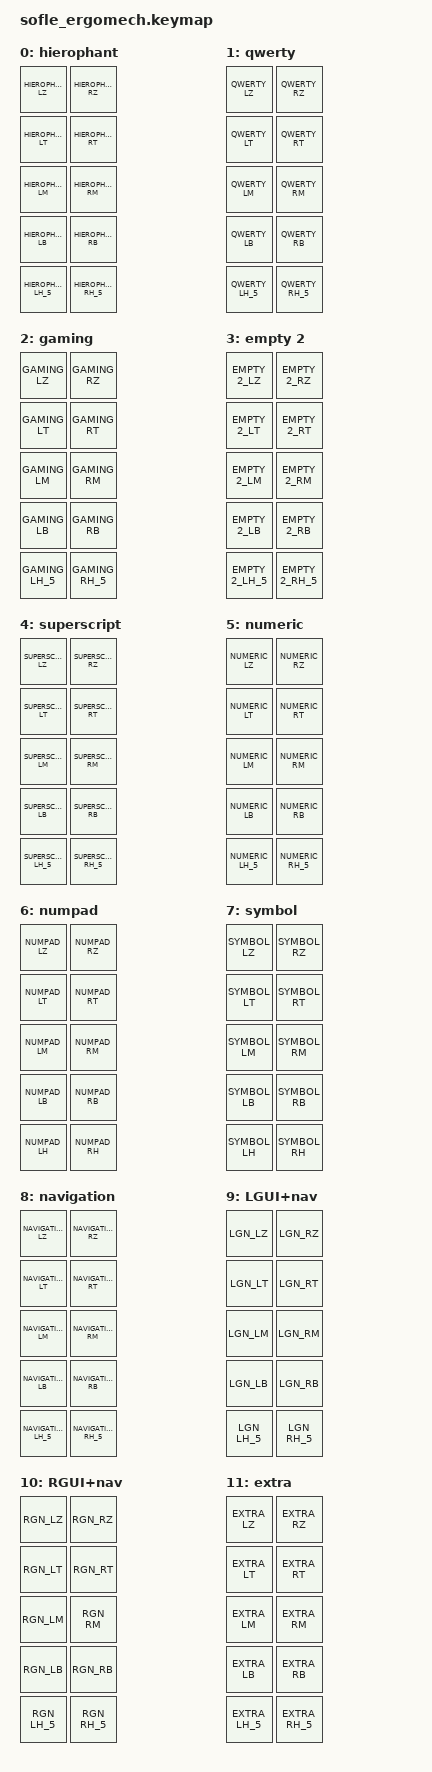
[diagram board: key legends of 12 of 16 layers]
#define CONFIG_WIRELESS

#include "zmk-helpers/key-labels/sofle.h"
#include "jjb.keymap"

/ {
    keymap {
        compatible = "zmk,keymap";

	hierophant_layer {
				display-name = "hierophant";
				bindings = <
HIEROPHANT_LZ HIEROPHANT_RZ
HIEROPHANT_LT HIEROPHANT_RT
HIEROPHANT_LM HIEROPHANT_RM
HIEROPHANT_LB HIEROPHANT_RB
HIEROPHANT_LH_5 HIEROPHANT_RH_5
				>;
            sensor-bindings = <&inc_dec_kp C_VOL_UP C_VOL_DN &inc_dec_kp PG_UP PG_DN>;
	};


        qwerty_layer {
            display-name = "qwerty";
            bindings = <
QWERTY_LZ QWERTY_RZ
QWERTY_LT QWERTY_RT
QWERTY_LM QWERTY_RM
QWERTY_LB QWERTY_RB
QWERTY_LH_5 QWERTY_RH_5
				>;				
            sensor-bindings = <&inc_dec_kp C_VOL_UP C_VOL_DN &inc_dec_kp PG_UP PG_DN>;
        };


        gaming_layer {
            display-name = "gaming";
            bindings = <
GAMING_LZ GAMING_RZ
GAMING_LT GAMING_RT
GAMING_LM GAMING_RM
GAMING_LB GAMING_RB
GAMING_LH_5 GAMING_RH_5
             >;
            sensor-bindings = <&inc_dec_kp C_VOL_UP C_VOL_DN &inc_dec_kp PG_UP PG_DN>;
        };

	empty_2_layer {
		display-name = "empty 2";
		bindings = <
EMPTY_2_LZ EMPTY_2_RZ
EMPTY_2_LT EMPTY_2_RT
EMPTY_2_LM EMPTY_2_RM
EMPTY_2_LB EMPTY_2_RB
EMPTY_2_LH_5 EMPTY_2_RH_5
				>;
            sensor-bindings = <&inc_dec_kp C_VOL_UP C_VOL_DN &inc_dec_kp PG_UP PG_DN>;
	};


        superscript_layer {
            display-name = "superscript";
            bindings = <
SUPERSCRIPT_LZ SUPERSCRIPT_RZ
SUPERSCRIPT_LT SUPERSCRIPT_RT
SUPERSCRIPT_LM SUPERSCRIPT_RM
SUPERSCRIPT_LB SUPERSCRIPT_RB
SUPERSCRIPT_LH_5 SUPERSCRIPT_RH_5
            >;
            sensor-bindings = <&inc_dec_kp C_VOL_UP C_VOL_DN &inc_dec_kp PG_UP PG_DN>;
        };


        numeric_layer {
            display-name = "numeric";
            bindings = <
NUMERIC_LZ NUMERIC_RZ
NUMERIC_LT NUMERIC_RT
NUMERIC_LM NUMERIC_RM
NUMERIC_LB NUMERIC_RB
NUMERIC_LH_5 NUMERIC_RH_5
            >;
            sensor-bindings = <&inc_dec_kp C_VOL_UP C_VOL_DN &inc_dec_kp PG_UP PG_DN>;
        };


        numpad_layer {
            display-name = "numpad";
            bindings = <
NUMPAD_LZ NUMPAD_RZ
NUMPAD_LT NUMPAD_RT
NUMPAD_LM NUMPAD_RM
NUMPAD_LB NUMPAD_RB
NUMPAD_LH NUMPAD_RH
            >;
        };

        /*
         * There was a numberline_layer here, and it had to go.
         *
         * Nothing defined NUMBERLINE_LZ or any of its siblings -- not in
         * jjb.keymap, not anywhere in the tree -- so this file has not compiled
         * for as long as those macros have been absent. `just build all` was
         * red on this target alone and nothing depended on it, so it went
         * unnoticed.
         *
         * Deleting rather than defining, because the layer was in the wrong
         * place as well as undefined: the shared layout pins layer INDICES
         * (SYMBOL 7, LIGHTING 13, BLUETOOTH 14, SYSTEM 15) and every board is
         * expected to list its layers in that order. Sitting between numpad and
         * symbol, this one pushed all eleven layers after it along by one, so
         * every `&mo SYMBOL` on this keyboard would have opened navigation.
         *
         * The sofle's number row is not lost with it: it is a full row on every
         * layer, carried by the _LZ / _RZ row macros the shared layout already
         * defines, which is why every other layer here has one.
         */


        symbol_layer {
            display-name = "symbol";
            bindings = <
SYMBOL_LZ SYMBOL_RZ
SYMBOL_LT SYMBOL_RT
SYMBOL_LM SYMBOL_RM
SYMBOL_LB SYMBOL_RB
SYMBOL_LH SYMBOL_RH
            >;
        };


        navigation_layer {
            display-name = "navigation";
            bindings = <
NAVIGATION_LZ NAVIGATION_RZ
NAVIGATION_LT NAVIGATION_RT
NAVIGATION_LM NAVIGATION_RM
NAVIGATION_LB NAVIGATION_RB
NAVIGATION_LH_5 NAVIGATION_RH_5
            >;
            sensor-bindings = <&inc_dec_kp C_VOL_UP C_VOL_DN &inc_dec_kp PG_UP PG_DN>;
        };


        mod_l_nav_layer {
            display-name = "LGUI+nav";
            bindings = <
LGN_LZ LGN_RZ
LGN_LT LGN_RT
LGN_LM LGN_RM
LGN_LB LGN_RB
LGN_LH_5 LGN_RH_5
            >;
            sensor-bindings = <&inc_dec_kp C_VOL_UP C_VOL_DN &inc_dec_kp PG_UP PG_DN>;
        };


        mod_r_nav_layer {
            display-name = "RGUI+nav";
            bindings = <
RGN_LZ RGN_RZ
RGN_LT RGN_RT
RGN_LM RGN_RM
RGN_LB RGN_RB
RGN_LH_5 RGN_RH_5
            >;
            sensor-bindings = <&inc_dec_kp C_VOL_UP C_VOL_DN &inc_dec_kp PG_UP PG_DN>;
        };


        extra_layer {
            display-name = "extra";
            bindings = <
EXTRA_LZ EXTRA_RZ
EXTRA_LT EXTRA_RT
EXTRA_LM EXTRA_RM
EXTRA_LB EXTRA_RB
EXTRA_LH_5 EXTRA_RH_5
            >;
            sensor-bindings = <&inc_dec_kp C_VOL_UP C_VOL_DN &inc_dec_kp PG_UP PG_DN>;
        };

        function_layer {
            display-name = "function";
            bindings = <
FUNCTION_LZ FUNCTION_RZ
FUNCTION_LT FUNCTION_RT
FUNCTION_LM FUNCTION_RM
FUNCTION_LB FUNCTION_RB
FUNCTION_LH_5 FUNCTION_RH_5
            >;
            sensor-bindings = <&inc_dec_kp C_VOL_UP C_VOL_DN &inc_dec_kp PG_UP PG_DN>;
        };

        lighting_layer {
            display-name = "lighting";
            bindings = <
LIGHTING_LZ LIGHTING_RZ
LIGHTING_LT LIGHTING_RT
LIGHTING_LM LIGHTING_RM
LIGHTING_LB LIGHTING_RB
LIGHTING_LH_5 LIGHTING_RH_5
            >;
            sensor-bindings = <&inc_dec_kp C_VOL_UP C_VOL_DN &inc_dec_kp PG_UP PG_DN>;
        };


        bluetooth_layer {
            display-name = "bluetooth";
            bindings = <
BLUETOOTH_LZ BLUETOOTH_RZ
BLUETOOTH_LT BLUETOOTH_RT
BLUETOOTH_LM BLUETOOTH_RM
BLUETOOTH_LB BLUETOOTH_RB
BLUETOOTH_LH_5 BLUETOOTH_RH_5
            >;
        };


        system_layer {
            display-name = "system";
            bindings = <
SYSTEM_LZ SYSTEM_RZ
SYSTEM_LT SYSTEM_RT
SYSTEM_LM SYSTEM_RM
SYSTEM_LB SYSTEM_RB
SYSTEM_LH_5 SYSTEM_RH_5
            >;
            sensor-bindings = <&inc_dec_kp C_VOL_UP C_VOL_DN &inc_dec_kp PG_UP PG_DN>;
        };


/*
        empty_layer {
            display-name = "empty";
            bindings = <
EMPTY_LZ EMPTY_RZ
EMPTY_LT EMPTY_RT
EMPTY_LM EMPTY_RM
EMPTY_LB EMPTY_RB
EMPTY_LH_5 EMPTY_RH_5
            >;
            sensor-bindings = <&inc_dec_kp C_VOL_UP C_VOL_DN &inc_dec_kp PG_UP PG_DN>;
        };
*/

     }; /* keymap */
}; // root node


